VERSION ""

NS_ :

BS_:

BU_: ECU

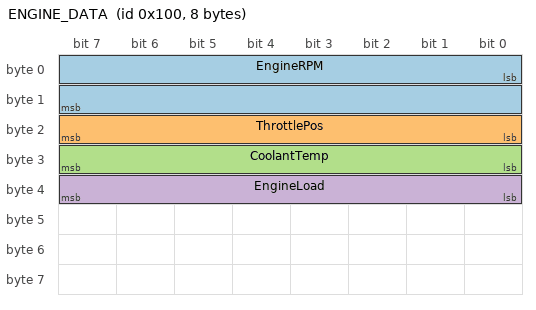
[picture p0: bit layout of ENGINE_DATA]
BO_ 256 ENGINE_DATA: 8 ECU
 SG_ EngineRPM : 0|16@1+ (0.25,0) [0|8000] "rpm" Vector__XXX
 SG_ ThrottlePos : 16|8@1+ (1,0) [0|100] "%" Vector__XXX
 SG_ CoolantTemp : 24|8@1+ (1,-40) [-40|150] "degC" Vector__XXX
 SG_ EngineLoad : 32|8@1+ (1,0) [0|100] "%" Vector__XXX

BO_ 512 VEHICLE_SPEED: 4 ECU
 SG_ VehicleSpeed : 0|16@1+ (0.01,0) [0|300] "km/h" Vector__XXX
 SG_ FuelLevel : 16|8@1+ (0.5,0) [0|100] "%" Vector__XXX
